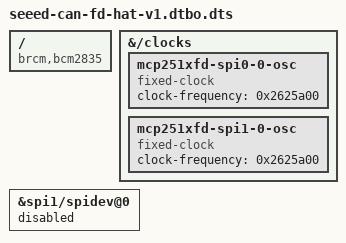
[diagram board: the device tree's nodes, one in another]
/dts-v1/;

/ {
	compatible = "brcm,bcm2835";

	fragment@0 {
		target = <0xffffffff>;

		__overlay__ {

			spi1_pins {
				brcm,pins = <0x13 0x14 0x15>;
				brcm,function = <0x03>;
				phandle = <0x01>;
			};

			spi1_cs_pins {
				brcm,pins = <0x12>;
				brcm,function = <0x01>;
				phandle = <0x02>;
			};
		};
	};

	fragment@1 {
		target = <0xffffffff>;

		__overlay__ {
			#address-cells = <0x01>;
			#size-cells = <0x00>;
			pinctrl-names = "default";
			pinctrl-0 = <0x01 0x02>;
			cs-gpios = <0xffffffff 0x12 0x01>;
			status = "okay";

			spidev@0 {
				compatible = "spidev";
				reg = <0x00>;
				#address-cells = <0x01>;
				#size-cells = <0x00>;
				spi-max-frequency = <0x7735940>;
				status = "disabled";
			};
		};
	};

	fragment@2 {
		target = <0xffffffff>;

		__overlay__ {
			status = "okay";
		};
	};

	fragment@3 {
		target = <0xffffffff>;

		__overlay__ {
			status = "disabled";
		};
	};

	fragment@4 {
		target = <0xffffffff>;

		__overlay__ {

			mcp251xfd_spi0_0_pins {
				brcm,pins = <0x19>;
				brcm,function = <0x00>;
				phandle = <0x03>;
			};
		};
	};

	fragment@5 {
		target-path = "/clocks";

		__overlay__ {

			mcp251xfd-spi0-0-osc {
				#clock-cells = <0x00>;
				compatible = "fixed-clock";
				clock-frequency = <0x2625a00>;
				phandle = <0x04>;
			};
		};
	};

	fragment@6 {
		target = <0xffffffff>;

		__overlay__ {
			status = "okay";
			#address-cells = <0x01>;
			#size-cells = <0x00>;

			mcp251xfd@0 {
				compatible = "microchip,mcp251xfd";
				reg = <0x00>;
				pinctrl-names = "default";
				pinctrl-0 = <0x03>;
				spi-max-frequency = <0x1312d00>;
				interrupt-parent = <0xffffffff>;
				interrupts = <0x19 0x08>;
				clocks = <0x04>;
			};
		};
	};

	fragment@7 {
		target-path = "spi1/spidev@0";

		__overlay__ {
			status = "disabled";
		};
	};

	fragment@8 {
		target = <0xffffffff>;

		__overlay__ {

			mcp251xfd_spi1_0_pins {
				brcm,pins = <0x18>;
				brcm,function = <0x00>;
				phandle = <0x05>;
			};
		};
	};

	fragment@9 {
		target-path = "/clocks";

		__overlay__ {

			mcp251xfd-spi1-0-osc {
				#clock-cells = <0x00>;
				compatible = "fixed-clock";
				clock-frequency = <0x2625a00>;
				phandle = <0x06>;
			};
		};
	};

	fragment@10 {
		target = <0xffffffff>;

		__overlay__ {
			status = "okay";
			#address-cells = <0x01>;
			#size-cells = <0x00>;

			mcp251xfd@0 {
				compatible = "microchip,mcp251xfd";
				reg = <0x00>;
				pinctrl-names = "default";
				pinctrl-0 = <0x05>;
				spi-max-frequency = <0x1312d00>;
				interrupt-parent = <0xffffffff>;
				interrupts = <0x18 0x08>;
				clocks = <0x06>;
			};
		};
	};

	__symbols__ {
		spi1_pins = "/fragment@0/__overlay__/spi1_pins";
		spi1_cs_pins = "/fragment@0/__overlay__/spi1_cs_pins";
		mcp251xfd_pins = "/fragment@4/__overlay__/mcp251xfd_spi0_0_pins";
		clk_mcp251xfd_osc = "/fragment@5/__overlay__/mcp251xfd-spi0-0-osc";
		mcp251xfd_pins_1 = "/fragment@8/__overlay__/mcp251xfd_spi1_0_pins";
		clk_mcp251xfd_osc_1 = "/fragment@9/__overlay__/mcp251xfd-spi1-0-osc";
	};

	__fixups__ {
		gpio = "/fragment@0:target:0\0/fragment@1/__overlay__:cs-gpios:0\0/fragment@4:target:0\0/fragment@6/__overlay__/mcp251xfd@0:interrupt-parent:0\0/fragment@8:target:0\0/fragment@10/__overlay__/mcp251xfd@0:interrupt-parent:0";
		spi1 = "/fragment@1:target:0\0/fragment@10:target:0";
		aux = "/fragment@2:target:0";
		spidev0 = "/fragment@3:target:0";
		spi0 = "/fragment@6:target:0";
	};

	__local_fixups__ {

		fragment@1 {

			__overlay__ {
				pinctrl-0 = <0x00 0x04>;
			};
		};

		fragment@6 {

			__overlay__ {

				mcp251xfd@0 {
					pinctrl-0 = <0x00>;
					clocks = <0x00>;
				};
			};
		};

		fragment@10 {

			__overlay__ {

				mcp251xfd@0 {
					pinctrl-0 = <0x00>;
					clocks = <0x00>;
				};
			};
		};
	};
};
